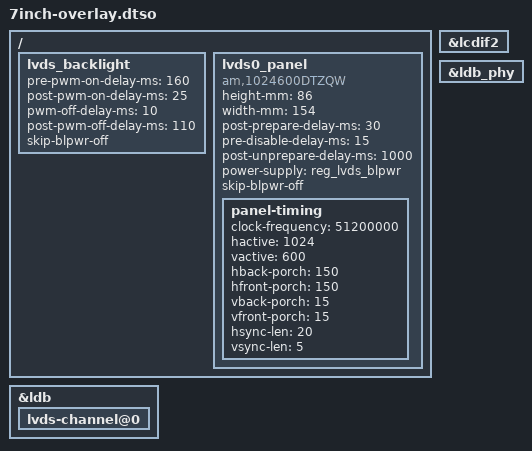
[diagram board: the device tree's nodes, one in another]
// SPDX-License-Identifier: (GPL-2.0+ OR MIT)
/*
 * Copyright 2023 ADLINK Technology Corp.
 *
 * Author: Po Cheng <po.cheng@adlinktech.com>
 */

/dts-v1/;
/plugin/;

/ {
	fragment@0 {
		target-path = "/";
		__overlay__ {
			lvds_backlight {
				pre-pwm-on-delay-ms = <160>;
				post-pwm-on-delay-ms = <25>;
				pwm-off-delay-ms = <10>;
				post-pwm-off-delay-ms = <110>;
				skip-blpwr-off;
				status = "okay";
			};
		};
	};

	fragment@1 {
		target-path = "/";
		__overlay__ {
			lvds0_panel {
				compatible = "am,1024600DTZQW", "panel-lvds";

				height-mm = <86>;
				width-mm = <154>;

				post-prepare-delay-ms = <30>;
				pre-disable-delay-ms = <15>;
				post-unprepare-delay-ms = <1000>;

				power-supply = <&reg_lvds_blpwr>;
				skip-blpwr-off;

				status = "okay";

				panel-timing {
					clock-frequency = <51200000>;
					hactive = <1024>;
					vactive = <600>;
					hback-porch = <150>;
					hfront-porch = <150>;
					vback-porch = <15>;
					vfront-porch = <15>;
					hsync-len = <20>;
					vsync-len = <5>;
				};
			};
		};
	};

	fragment@2 {
		target = <&ldb>;
		__overlay__ {
			status = "okay";
			lvds-channel@0 {
				status = "okay";
			};
		};
	};

	fragment@3 {
		target = <&lcdif2>;
		__overlay__ {
			status = "okay";
		};
	};

	fragment@4 {
		target = <&ldb_phy>;
		__overlay__ {
			status = "okay";
		};
	};
};

